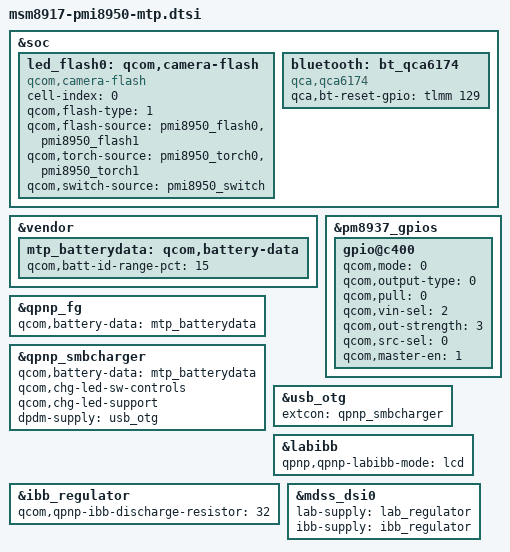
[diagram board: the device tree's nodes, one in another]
/*
 * Copyright (c) 2015-2018, The Linux Foundation. All rights reserved.
 *
 * This program is free software; you can redistribute it and/or modify
 * it under the terms of the GNU General Public License version 2 and
 * only version 2 as published by the Free Software Foundation.
 *
 * This program is distributed in the hope that it will be useful,
 * but WITHOUT ANY WARRANTY; without even the implied warranty of
 * MERCHANTABILITY or FITNESS FOR A PARTICULAR PURPOSE.  See the
 * GNU General Public License for more details.
 */

#include "pmi8950.dtsi"
#include "msm8917-mtp.dtsi"

&soc {
	led_flash0: qcom,camera-flash {
		cell-index = <0>;
		compatible = "qcom,camera-flash";
		qcom,flash-type = <1>;
		qcom,flash-source = <&pmi8950_flash0 &pmi8950_flash1>;
		qcom,torch-source = <&pmi8950_torch0 &pmi8950_torch1>;
		qcom,switch-source = <&pmi8950_switch>;
	};

	bluetooth: bt_qca6174 {
		compatible = "qca,qca6174";
		qca,bt-reset-gpio = <&tlmm 129 0>; /* BT_EN */
	};
};

&vendor{
	mtp_batterydata: qcom,battery-data {
		qcom,batt-id-range-pct = <15>;
		#include "batterydata-itech-3000mah.dtsi"
		#include "batterydata-ascent-3450mAh.dtsi"
	};
};

&pm8937_gpios {
	gpio@c400 {
		qcom,mode = <0>;
		qcom,output-type = <0>;
		qcom,pull = <0>;
		qcom,vin-sel = <2>;
		qcom,out-strength = <3>;
		qcom,src-sel = <0>;
		qcom,master-en = <1>;
		status = "okay";
	};
};

&qpnp_fg {
	qcom,battery-data = <&mtp_batterydata>;
};

&qpnp_smbcharger {
	qcom,battery-data = <&mtp_batterydata>;
	qcom,chg-led-sw-controls;
	qcom,chg-led-support;
	dpdm-supply = <&usb_otg>;
};

&usb_otg {
	extcon = <&qpnp_smbcharger>;
};

&labibb {
	status = "ok";
	qpnp,qpnp-labibb-mode = "lcd";
};

&ibb_regulator {
	qcom,qpnp-ibb-discharge-resistor = <32>;
};

&mdss_dsi0 {
	lab-supply = <&lab_regulator>;
	ibb-supply = <&ibb_regulator>;
};
